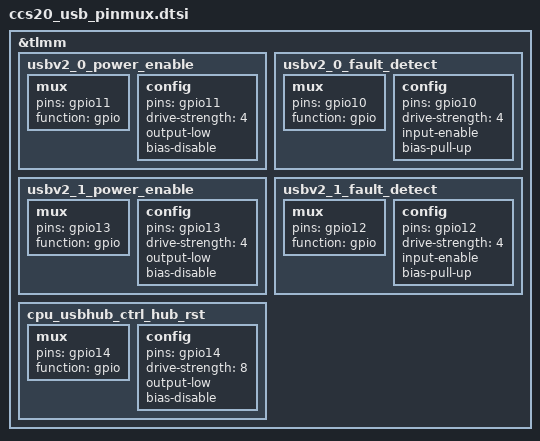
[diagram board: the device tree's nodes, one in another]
/*
 * USB pin states for CCS20 - generated by usb_dts_tool from the PinMux workbook.
 * Every NEEDS REVIEW comment is an open decision; nothing marked so is verified.
 * Format: default format (the vendor BSP style of the samples: tabs, mux{} / config{}, 'label: label').
 */

&tlmm {
	usbv2_0_power_enable: usbv2_0_power_enable {
		mux {
			pins = "gpio11";
			function = "gpio";
		};
		config {
			pins = "gpio11";
			drive-strength = <4>;
			output-low;
			/* source: Excel ResetValue "0: low" */
			bias-disable;
		};
	};

	usbv2_0_fault_detect: usbv2_0_fault_detect {
		mux {
			pins = "gpio10";
			function = "gpio";
		};
		config {
			pins = "gpio10";
			drive-strength = <4>;
			input-enable;
			bias-pull-up;
		};
	};

	usbv2_1_power_enable: usbv2_1_power_enable {
		mux {
			pins = "gpio13";
			function = "gpio";
		};
		config {
			pins = "gpio13";
			drive-strength = <4>;
			output-low;
			/* source: Excel ResetValue "0: low" */
			bias-disable;
		};
	};

	usbv2_1_fault_detect: usbv2_1_fault_detect {
		mux {
			pins = "gpio12";
			function = "gpio";
		};
		config {
			pins = "gpio12";
			drive-strength = <4>;
			input-enable;
			bias-pull-up;
		};
	};

	cpu_usbhub_ctrl_hub_rst: cpu_usbhub_ctrl_hub_rst {
		mux {
			pins = "gpio14";
			function = "gpio";
		};
		config {
			pins = "gpio14";
			drive-strength = <8>;
			output-low;
			/* source: Excel ResetValue "0: low" */
			bias-disable;
		};
	};
};
